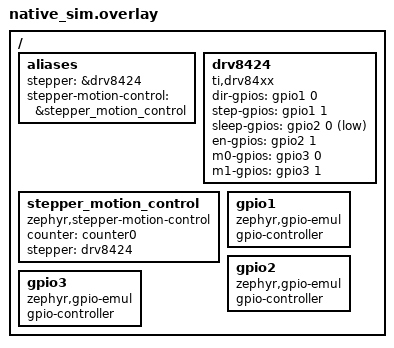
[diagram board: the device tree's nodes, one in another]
/*
 * Copyright (c) 2024 Navimatix GmbH
 * SPDX-License-Identifier: Apache-2.0
 */

#include <zephyr/dt-bindings/gpio/gpio.h>

/ {
	aliases {
		stepper = &drv8424;
		stepper-motion-control = &stepper_motion_control;
	};
};

/ {
	drv8424: drv8424 {
		status = "okay";
		compatible = "ti,drv84xx";

		dir-gpios = <&gpio1 0 0>; /* D3 */
		step-gpios = <&gpio1 1 0>; /* D4 */
		sleep-gpios = <&gpio2 0 GPIO_ACTIVE_LOW>; /* D2 */
		en-gpios = <&gpio2 1 0>; /* 5 */
		m0-gpios = <&gpio3 0 0>;
		m1-gpios = <&gpio3 1 0>;

		#address-cells = <1>;
		#size-cells = <0>;
		#stepper-motor-cells = <0>;
	};

	stepper_motion_control: stepper_motion_control {
		compatible = "zephyr,stepper-motion-control";
		status = "okay";
		counter = <&counter0>;
		stepper = <&drv8424>;
	};

	gpio1: gpio1 {
		compatible = "zephyr,gpio-emul";
		#gpio-cells = <0x2>;
		status = "okay";
		gpio-controller;
	};

	gpio2: gpio2 {
		compatible = "zephyr,gpio-emul";
		#gpio-cells = <0x2>;
		status = "okay";
		gpio-controller;
	};

	gpio3: gpio3 {
		compatible = "zephyr,gpio-emul";
		#gpio-cells = <0x2>;
		status = "okay";
		gpio-controller;
	};
};
